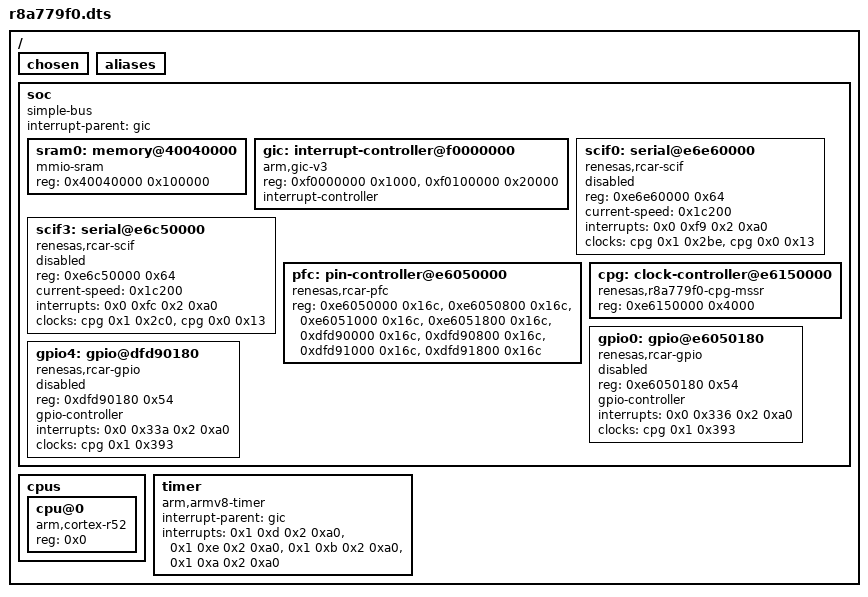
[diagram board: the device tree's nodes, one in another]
/dts-v1/;

/ {
	#address-cells = < 0x1 >;
	#size-cells = < 0x1 >;
	chosen {
	};
	aliases {
	};
	soc {
		#address-cells = < 0x1 >;
		#size-cells = < 0x1 >;
		compatible = "simple-bus";
		ranges;
		interrupt-parent = < &gic >;
		sram0: memory@40040000 {
			compatible = "mmio-sram";
			reg = < 0x40040000 0x100000 >;
		};
		gic: interrupt-controller@f0000000 {
			compatible = "arm,gic-v3", "arm,gic";
			reg = < 0xf0000000 0x1000 >, < 0xf0100000 0x20000 >;
			interrupt-controller;
			#interrupt-cells = < 0x4 >;
			status = "okay";
			phandle = < 0x1 >;
		};
		scif0: serial@e6e60000 {
			compatible = "renesas,rcar-scif";
			reg = < 0xe6e60000 0x64 >;
			current-speed = < 0x1c200 >;
			status = "disabled";
			interrupts = < 0x0 0xf9 0x2 0xa0 >;
			clocks = < &cpg 0x1 0x2be >, < &cpg 0x0 0x13 >;
		};
		scif3: serial@e6c50000 {
			compatible = "renesas,rcar-scif";
			reg = < 0xe6c50000 0x64 >;
			current-speed = < 0x1c200 >;
			status = "disabled";
			interrupts = < 0x0 0xfc 0x2 0xa0 >;
			clocks = < &cpg 0x1 0x2c0 >, < &cpg 0x0 0x13 >;
		};
		pfc: pin-controller@e6050000 {
			compatible = "renesas,rcar-pfc";
			reg = < 0xe6050000 0x16c >, < 0xe6050800 0x16c >, < 0xe6051000 0x16c >, < 0xe6051800 0x16c >, < 0xdfd90000 0x16c >, < 0xdfd90800 0x16c >, < 0xdfd91000 0x16c >, < 0xdfd91800 0x16c >;
		};
		cpg: clock-controller@e6150000 {
			compatible = "renesas,r8a779f0-cpg-mssr";
			reg = < 0xe6150000 0x4000 >;
			#clock-cells = < 0x2 >;
			phandle = < 0x2 >;
		};
		gpio0: gpio@e6050180 {
			compatible = "renesas,rcar-gpio";
			reg = < 0xe6050180 0x54 >;
			#gpio-cells = < 0x2 >;
			gpio-controller;
			interrupts = < 0x0 0x336 0x2 0xa0 >;
			clocks = < &cpg 0x1 0x393 >;
			status = "disabled";
		};
		gpio4: gpio@dfd90180 {
			compatible = "renesas,rcar-gpio";
			reg = < 0xdfd90180 0x54 >;
			#gpio-cells = < 0x2 >;
			gpio-controller;
			interrupts = < 0x0 0x33a 0x2 0xa0 >;
			clocks = < &cpg 0x1 0x393 >;
			status = "disabled";
		};
	};
	cpus {
		#address-cells = < 0x1 >;
		#size-cells = < 0x0 >;
		cpu@0 {
			device_type = "cpu";
			compatible = "arm,cortex-r52";
			reg = < 0x0 >;
		};
	};
	timer {
		compatible = "arm,armv8-timer";
		interrupt-parent = < &gic >;
		interrupts = < 0x1 0xd 0x2 0xa0 >, < 0x1 0xe 0x2 0xa0 >, < 0x1 0xb 0x2 0xa0 >, < 0x1 0xa 0x2 0xa0 >;
	};
};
